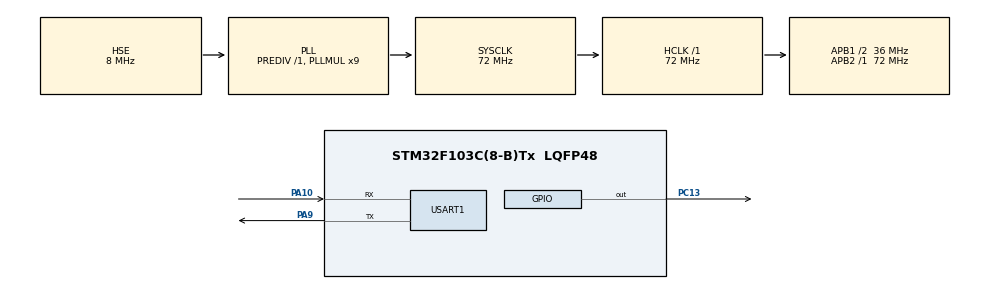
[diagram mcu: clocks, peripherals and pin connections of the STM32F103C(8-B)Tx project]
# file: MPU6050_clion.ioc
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Dma.Request0=USART1_TX
Dma.USART1_TX.0.Direction=DMA_MEMORY_TO_PERIPH
Dma.USART1_TX.0.Instance=DMA1_Channel4
Dma.USART1_TX.0.MemDataAlignment=DMA_MDATAALIGN_BYTE
Dma.USART1_TX.0.MemInc=DMA_MINC_ENABLE
Dma.USART1_TX.0.Mode=DMA_NORMAL
Dma.USART1_TX.0.PeriphDataAlignment=DMA_PDATAALIGN_BYTE
Dma.USART1_TX.0.PeriphInc=DMA_PINC_DISABLE
Dma.USART1_TX.0.Priority=DMA_PRIORITY_MEDIUM
Mcu.Family=STM32F1
Mcu.Name=STM32F103C(8-B)Tx
Mcu.Package=LQFP48
NVIC.DMA1_Channel4_IRQn=true\:0\:0\:false\:false\:true\:false\:true
NVIC.PriorityGroup=NVIC_PRIORITYGROUP_4
NVIC.USART1_IRQn=true\:0\:0\:false\:false\:true\:true\:true
PA10.Mode=Asynchronous
PA10.Signal=USART1_RX
PA13.Mode=Trace_Asynchronous_SW
PA13.Signal=SYS_JTMS-SWDIO
PA14.Mode=Trace_Asynchronous_SW
PA14.Signal=SYS_JTCK-SWCLK
PA9.Mode=Asynchronous
PA9.Signal=USART1_TX
PB3.Mode=Trace_Asynchronous_SW
PB3.Signal=SYS_JTDO-TRACESWO
PC13-TAMPER-RTC.Signal=GPIO_Output
PD0-OSC_IN.Mode=HSE-External-Oscillator
PD0-OSC_IN.Signal=RCC_OSC_IN
PD1-OSC_OUT.Mode=HSE-External-Oscillator
PD1-OSC_OUT.Signal=RCC_OSC_OUT
ProjectManager.HeapSize=0x200
ProjectManager.StackSize=0x400
ProjectManager.TargetToolchain=STM32CubeIDE
RCC.AHBFreq_Value=72000000
RCC.APB1CLKDivider=RCC_HCLK_DIV2
RCC.APB1Freq_Value=36000000
RCC.APB1TimFreq_Value=72000000
RCC.APB2Freq_Value=72000000
RCC.APB2TimFreq_Value=72000000
RCC.HCLKFreq_Value=72000000
RCC.PLLMUL=RCC_PLL_MUL9
RCC.PLLSourceVirtual=RCC_PLLSOURCE_HSE
RCC.SYSCLKFreq_VALUE=72000000
RCC.SYSCLKSource=RCC_SYSCLKSOURCE_PLLCLK
RCC.USBFreq_Value=72000000
USART1.VirtualMode=VM_ASYNC
board=custom

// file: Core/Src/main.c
/* USER CODE BEGIN Header */
/**
  ******************************************************************************
  * @file           : main.c
  * @brief          : Main program body
  ******************************************************************************
  * @attention
  *
  * <h2><center>&copy; Copyright (c) 2021 STMicroelectronics.
  * All rights reserved.</center></h2>
  *
  * This software component is licensed by ST under BSD 3-Clause license,
  * the "License"; You may not use this file except in compliance with the
  * License. You may obtain a copy of the License at:
  *                        opensource.org/licenses/BSD-3-Clause
  *
  ******************************************************************************
  */
/* USER CODE END Header */
#include "main.h"
#include "dma.h"
#include "usart.h"
#include "gpio.h"

/* USER CODE BEGIN Includes */
#include "mpuiic.h"
#include "inv_mpu.h"
#include "mpu6050.h"
/* USER CODE END Includes */

void SystemClock_Config(void);

/* USER CODE BEGIN 0 */
int8_t problem_init = 20;
int8_t sendbuff[] = {0xfb};
float pitch,roll,yaw; 		//欧拉角
short aacx,aacy,aacz;		//加速度传感器原始数据
short gyrox,gyroy,gyroz;	//陀螺仪原始数据
short temp;					//温度
short temperature;
/* USER CODE END 0 */

int main(void)
{

  /* MCU Configuration--------------------------------------------------------*/

  /* Reset of all peripherals, Initializes the Flash interface and the Systick. */
  HAL_Init();

  /* Configure the system clock */
  SystemClock_Config();

  /* Initialize all configured peripherals */
  MX_GPIO_Init();
  MX_DMA_Init();
  MX_USART1_UART_Init();
  /* USER CODE BEGIN 2 */
    MPU_Init();
    HAL_Delay(1000);  //wait for MPU6050
    while(problem_init) {
        problem_init = mpu_dmp_init();
        HAL_UART_Transmit_DMA(&huart1, &problem_init, sizeof(problem_init));
        checkDevice(MPU_WRITE);
        HAL_Delay(200);
        //sendbuff=MPU_Read_Len(,MPU_DEVICE_ID_REG);  // check the MPU6050 ID
        }
    uint8_t tmp[2];
    unsigned short fifo_count;
  /* USER CODE END 2 */

  /* Infinite loop */
  while (1)
  {

      //HAL_UART_Transmit_DMA(&huart1,&sendbuff,sizeof (sendbuff));
      //mpu_reset_fifo();
      //HAL_Delay(5);

      //if( mpu_dmp_get_data(&pitch,&roll,&yaw) == 0 ) {HAL_UART_Transmit_DMA(&huart1, &sendbuff, sizeof(sendbuff));}
      //problem_init =mpu_dmp_get_data(&pitch,&roll,&yaw);
      //HAL_UART_Transmit_DMA(&huart1, &problem_init, sizeof(problem_init));

        while( mpu_dmp_get_data(&pitch,&roll,&yaw) == 0 );
/*      MPU_Read_Fifocount(tmp);
      fifo_count = (tmp[0] << 8) | tmp[1];
      //HAL_UART_Transmit_DMA(&huart1, &fifo_count, sizeof(fifo_count));
      //HAL_UART_Transmit_DMA(&huart1, &sendbuff, sizeof(sendbuff));
      if(260<fifo_count ) {
          if (mpu_dmp_get_data(&pitch, &roll, &yaw) != 0);
          mpu_reset_fifo();
          MPU_Read_Fifocount(tmp);
          fifo_count = (tmp[0] << 8) | tmp[1];
      }          */
      temperature = MPU_Get_Temperature();    //得到温度值
      //HAL_UART_Transmit_DMA(&huart1,&temperature,sizeof (temperature));
      MPU_Get_Accelerometer(&aacx, &aacy, &aacz);    //得到加速度传感器数据
      MPU_Get_Gyroscope(&gyrox, &gyroy, &gyroz);    //得到陀螺仪数据

  }
}

void SystemClock_Config(void)
{
  RCC_OscInitTypeDef RCC_OscInitStruct = {0};
  RCC_ClkInitTypeDef RCC_ClkInitStruct = {0};

  /** Initializes the RCC Oscillators according to the specified parameters
  * in the RCC_OscInitTypeDef structure.
  */
  RCC_OscInitStruct.OscillatorType = RCC_OSCILLATORTYPE_HSE;
  RCC_OscInitStruct.HSEState = RCC_HSE_ON;
  RCC_OscInitStruct.HSEPredivValue = RCC_HSE_PREDIV_DIV1;
  RCC_OscInitStruct.HSIState = RCC_HSI_ON;
  RCC_OscInitStruct.PLL.PLLState = RCC_PLL_ON;
  RCC_OscInitStruct.PLL.PLLSource = RCC_PLLSOURCE_HSE;
  RCC_OscInitStruct.PLL.PLLMUL = RCC_PLL_MUL9;
  if (HAL_RCC_OscConfig(&RCC_OscInitStruct) != HAL_OK)
  {
    Error_Handler();
  }
  /** Initializes the CPU, AHB and APB buses clocks
  */
  RCC_ClkInitStruct.ClockType = RCC_CLOCKTYPE_HCLK|RCC_CLOCKTYPE_SYSCLK
                              |RCC_CLOCKTYPE_PCLK1|RCC_CLOCKTYPE_PCLK2;
  RCC_ClkInitStruct.SYSCLKSource = RCC_SYSCLKSOURCE_PLLCLK;
  RCC_ClkInitStruct.AHBCLKDivider = RCC_SYSCLK_DIV1;
  RCC_ClkInitStruct.APB1CLKDivider = RCC_HCLK_DIV2;
  RCC_ClkInitStruct.APB2CLKDivider = RCC_HCLK_DIV1;

  if (HAL_RCC_ClockConfig(&RCC_ClkInitStruct, FLASH_LATENCY_2) != HAL_OK)
  {
    Error_Handler();
  }
}

void Error_Handler(void)
{
  __disable_irq();
  while (1)
  {
  }
}

/************************ (C) COPYRIGHT STMicroelectronics *****END OF FILE****/
